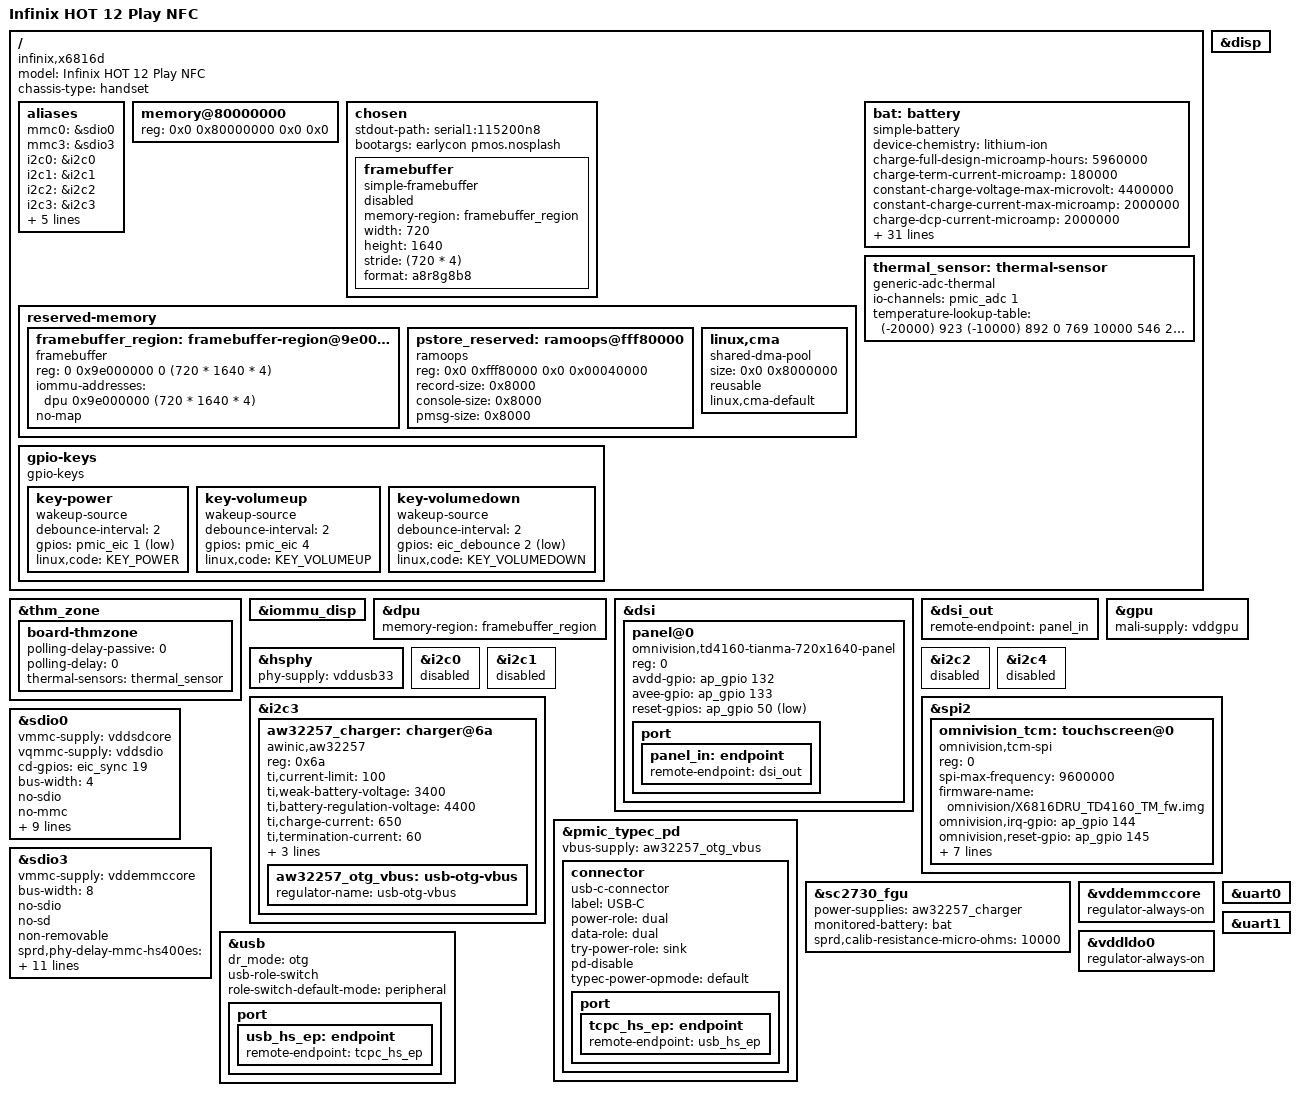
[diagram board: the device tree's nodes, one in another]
// SPDX-License-Identifier: (GPL-2.0 OR MIT)
/*
 * Copyright (C) 2026 Veynamer <veyr1thalone@gmail.com>
 */

/dts-v1/;

#include <dt-bindings/input/input.h>
#include <dt-bindings/usb/pd.h>
#include "ums512.dtsi"
#include "sc2730.dtsi"

/ {
	model = "Infinix HOT 12 Play NFC";
	compatible = "infinix,x6816d", "sprd,ums512";
	chassis-type = "handset";

	aliases {
		mmc0 = &sdio0;
		mmc3 = &sdio3;
		i2c0 = &i2c0;
		i2c1 = &i2c1;
		i2c2 = &i2c2;
		i2c3 = &i2c3;
		i2c4 = &i2c4;
		spi0 = &spi0;
		spi1 = &spi1;
		spi2 = &spi2;
		spi3 = &spi3;
	};

	memory@80000000 {
		device_type = "memory";
		/* We expect the bootloader to fill in the reg */
		reg = <0x0 0x80000000 0x0 0x0>;
	};

	chosen {
		stdout-path = "serial1:115200n8";
		bootargs = "earlycon pmos.nosplash";
		framebuffer {
			compatible = "simple-framebuffer";
			memory-region = <&framebuffer_region>;
			width = <720>;
			height = <1640>;
			stride = <(720 * 4)>;
			format = "a8r8g8b8";

			status = "disabled";
		};
	};

	reserved-memory {
		#address-cells = <2>;
		#size-cells = <2>;
		ranges;

		framebuffer_region: framebuffer-region@9e000000 {
			compatible = "framebuffer";
			reg = <0 0x9e000000 0 (720 * 1640 * 4)>;
			iommu-addresses = <&dpu 0x9e000000 (720 * 1640 * 4)>;
			no-map;
		};

		pstore_reserved: ramoops@fff80000 {
			compatible = "ramoops";
			reg = <0x0 0xfff80000 0x0 0x00040000>;
			record-size = <0x8000>;
			console-size = <0x8000>;
			pmsg-size = <0x8000>;
		};

		linux,cma {
			compatible = "shared-dma-pool";
			size = <0x0 0x8000000>;
			reusable;
			linux,cma-default;
		};
	};

	bat: battery {
		compatible = "simple-battery";
		device-chemistry = "lithium-ion";
		charge-full-design-microamp-hours = <5960000>;
		charge-term-current-microamp = <180000>;
		constant-charge-voltage-max-microvolt = <4400000>;
		constant-charge-current-max-microamp = <2000000>;
		charge-dcp-current-microamp = <2000000>;
		charge-cdp-current-microamp = <2000000>;
		charge-sdp-current-microamp = <500000>;
		charge-unknown-current-microamp = <1000000>;
		unknown-jeita-temp-table = <1000 1030 0 4400000
			1150 1180 500000 4400000
			1450 1420 1000000 4400000
			1600 1570 500000 4100000>;
		sdp-jeita-temp-table = <1000 1030 0 4400000
			1150 1180 500000 4400000
			1450 1420 500000 4400000
			1600 1570 500000 4100000>;
		cdp-jeita-temp-table = <1000 1030 0 4400000
			1150 1180 700000 4400000
			1450 1420 1150000 4400000
			1600 1570 700000 4100000>;
		dcp-jeita-temp-table = <1000 1030 0 4400000
			1150 1180 700000 4400000
			1450 1420 2000000 4400000
			1600 1570 700000 4100000>;
		voltage-min-design-microvolt = <3450000>;
		voltage-max-design-microvolt = <4340000>;
		factory-internal-resistance-micro-ohms = <130000>;
		resistance-temp-table = <45 77>, <25 100>, <10 546>,
				<0 769>, <(-10) 892>, <(-20) 923>;
		voltage-temp-table = <1095000 (-200)>, <986000 (-150)>,
				<878000 (-100)>, <775000 (-50)>, <678000 0>,
				<590000 50>, <510000 100>, <440000 150>,
				<378000 200>, <324000 250>, <278000 300>,
				<238000 350>, <204000 400>, <175000 450>,
				<150000 500>, <129000 550>, <111000 600>,
				<96000 650>;
		ocv-capacity-celsius = <20>;
		ocv-capacity-table-0 = <4342104 100>, <4323024 95>,
				<4265840 90>, <4191992 85>,
				<4142032 80>, <4082680 75>,
				<4040480 70>, <3986216 65>,
				<3941512 60>, <3890168 55>,
				<3853000 50>, <3825648 45>,
				<3805040 40>, <3787760 35>,
				<3775920 30>, <3767088 25>,
				<3750960 20>, <3725168 15>,
				<3693000 10>, <3675000 5>,
				<3400000 0>;
	};

	gpio-keys {
		compatible = "gpio-keys";

		key-power {
			wakeup-source;
			debounce-interval = <2>;
			gpios = <&pmic_eic 1 GPIO_ACTIVE_LOW>;
			linux,code = <KEY_POWER>;
		};

		key-volumeup {
			wakeup-source;
			debounce-interval = <2>;
			gpios = <&pmic_eic 4 GPIO_ACTIVE_HIGH>;
			linux,code = <KEY_VOLUMEUP>;
		};

		key-volumedown {
			wakeup-source;
			debounce-interval = <2>;
			gpios = <&eic_debounce 2 GPIO_ACTIVE_LOW>;
			linux,code = <KEY_VOLUMEDOWN>;
		};
	};

	thermal_sensor: thermal-sensor {
		compatible = "generic-adc-thermal";
		#thermal-sensor-cells = <0>;
		io-channels = <&pmic_adc 1>;
		io-channel-names = "sensor-channel";
		temperature-lookup-table = <
			(-20000) 923
			(-10000) 892
			0       769
			10000   546
			25000   100
			45000   77
		>;
	};
};

&thm_zone {
	board-thmzone {
		polling-delay-passive = <0>;
		polling-delay = <0>;
		thermal-sensors = <&thermal_sensor>;
	};
};

&iommu_disp {
	status = "okay";
};

&disp {
	status = "okay";
};

&dpu {
	status = "okay";
	memory-region = <&framebuffer_region>;
};

&dsi {
	status = "okay";

	#address-cells = <1>;
	#size-cells = <0>;

	panel@0 {
		compatible = "omnivision,td4160-tianma-720x1640-panel";
		reg = <0>;
		avdd-gpio = <&ap_gpio 132 GPIO_ACTIVE_HIGH>;
		avee-gpio = <&ap_gpio 133 GPIO_ACTIVE_HIGH>;
		reset-gpios = <&ap_gpio 50 GPIO_ACTIVE_LOW>;
		/*backlight = <&backlight>;*/

		port {
			panel_in: endpoint {
				remote-endpoint = <&dsi_out>;
			};
		};
	};
};

&dsi_out {
	remote-endpoint = <&panel_in>;
};

&gpu {
	mali-supply = <&vddgpu>;
	status = "okay";
};

&hsphy {
	status = "okay";
	phy-supply = <&vddusb33>;
};

&i2c0 {
	status = "disabled";
	#address-cells = <1>;
	#size-cells = <0>;

	/* camera sensor */
	/* sub sensor */
};

&i2c1 {
	status = "disabled";
	#address-cells = <1>;
	#size-cells = <0>;

	/* camera sensor */
};

&i2c2 {
	status = "disabled";
	#address-cells = <1>;
	#size-cells = <0>;

	/* ak4377 @ 10 */
};

&i2c3 {
	status = "okay";
	#address-cells = <1>;
	#size-cells = <0>;

	aw32257_charger: charger@6a {
		compatible = "awinic,aw32257";
		reg = <0x6a>;
		ti,current-limit = <100>;
		ti,weak-battery-voltage = <3400>;
		ti,battery-regulation-voltage = <4400>;
		ti,charge-current = <650>;
		ti,termination-current = <60>;
		ti,resistor-sense = <56>;
		monitored-battery = <&bat>;
		ti,usb-charger-detection = <&pmic_bc1p2>;

		aw32257_otg_vbus: usb-otg-vbus {
			regulator-name = "usb-otg-vbus";
		};
	};

	/* pn557: nfc@28 */
};

&i2c4 {
	status = "disabled";
	#address-cells = <1>;
	#size-cells = <0>;

	/* sprd,flash-ocp81375 reg = <0x63>
	 *	   st,stmvl53l0 @ 52
	 *	   ams,tcs3430 @ 39
	 *	   bias ocp2131 @ 3e
	 */
};

&spi2 {
	#address-cells = <1>;
	#size-cells = <0>;

	status = "okay";

	omnivision_tcm: touchscreen@0 {
		compatible = "omnivision,tcm-spi";
		reg = <0>;

		spi-max-frequency = <9600000>;

		firmware-name = "omnivision/X6816DRU_TD4160_TM_fw.img";

		omnivision,irq-gpio = <&ap_gpio 144 GPIO_ACTIVE_HIGH>;
		omnivision,reset-gpio = <&ap_gpio 145 GPIO_ACTIVE_HIGH>;
		omnivision,irq-on-state = <0>;
		omnivision,reset-on-state = <0>;

		omnivision,reset-active-ms = <20>;
		omnivision,reset-delay-ms = <200>;
		omnivision,spi-mode = <3>;
		omnivision,byte-delay-us = <0>;
		omnivision,block-delay-us = <0>;
	};
};

&pmic_typec_pd {
	status = "okay";
	vbus-supply = <&aw32257_otg_vbus>;

	connector {
		compatible = "usb-c-connector";
		label = "USB-C";
		power-role = "dual";
		data-role = "dual";
		try-power-role = "sink";
		pd-disable;
		typec-power-opmode = "default";

		port {
			tcpc_hs_ep: endpoint {
				remote-endpoint = <&usb_hs_ep>;
			};
		};
	};
};

&sc2730_fgu {
	power-supplies = <&aw32257_charger>;
	monitored-battery = <&bat>;
	sprd,calib-resistance-micro-ohms = <10000>;

	status = "okay";
};

/* SD card */
&sdio0 {
	status = "okay";
	vmmc-supply = <&vddsdcore>;
	vqmmc-supply = <&vddsdio>;
	cd-gpios = <&eic_sync 19 GPIO_ACTIVE_HIGH>;
	bus-width = <4>;
	no-sdio;
	no-mmc;
	sprd,phy-delay-sd-uhs-sdr104 = <0x7f 0x73 0x72 0x72>;
	sprd,phy-delay-sd-uhs-sdr50 = <0x6e 0x7f 0x01 0x01>;
	sprd,phy-delay-sd-highspeed = <0x7f 0x1a 0x9a 0x9a>;
	sprd,phy-delay-legacy = <0x7f 0x1a 0x9a 0x9a>;
	sd-uhs-sdr104;
	sd-uhs-sdr50;
};

/* EMMC storage */
&sdio3 {
	status = "okay";
	vmmc-supply = <&vddemmccore>;
	bus-width = <8>;
	no-sdio;
	no-sd;
	non-removable;
	sprd,phy-delay-mmc-hs400es = <0x40 0x7f 0x2d 0x2d>;
	sprd,phy-delay-mmc-hs400 = <0x3f 0xdf 0x2f 0x2f>;
	sprd,phy-delay-mmc-hs200 = <0x7f 0xde 0xd4 0xd4>;
	sprd,phy-delay-mmc-ddr52 = <0x3e 0x37 0x24 0x24>;
	sprd,phy-delay-mmc-highspeed = <0x60 0xb7 0x34 0x34>;
	cap-mmc-hw-reset;
	mmc-hs400-enhanced-strobe;
	mmc-hs400-1_8v;
	mmc-hs200-1_8v;
	mmc-ddr-1_8v;
};

&vddemmccore {
	regulator-always-on;
};

&vddldo0 {
	regulator-always-on;
};

&uart0 {
	status = "okay";
};

&uart1 {
	status = "okay";
};

&usb {
	dr_mode = "otg";
	usb-role-switch;
	role-switch-default-mode = "peripheral";
	status = "okay";

	port {
		usb_hs_ep: endpoint {
			remote-endpoint = <&tcpc_hs_ep>;
		};
	};
};

